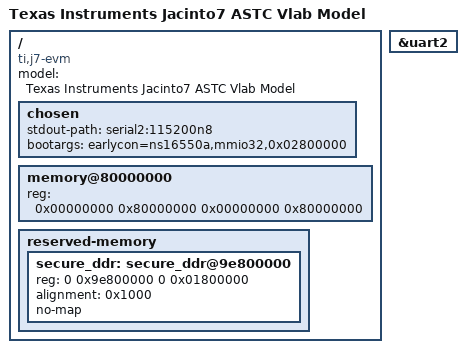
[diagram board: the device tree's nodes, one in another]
// SPDX-License-Identifier: GPL-2.0
/*
 * Device Tree Source for Jacinto7 ASTC VLAB Model
 *
 * Copyright (C) 2016-2017 Texas Instruments Incorporated - http://www.ti.com/
 */

/dts-v1/;

#include "k3-j7.dtsi"
#include "k3-j7-hexa-core.dtsi"

/ {
	compatible =  "ti,j7-evm", "ti,j7";
	model = "Texas Instruments Jacinto7 ASTC Vlab Model";

	chosen {
		stdout-path = "serial2:115200n8";
		bootargs = "earlycon=ns16550a,mmio32,0x02800000";
	};

	memory@80000000 {
		device_type = "memory";
		/* Claim 2GB RAM -> MUST be in sync with Python script*/
		reg = <0x00000000 0x80000000 0x00000000 0x80000000>;
	};

	reserved-memory {
		#address-cells = <2>;
		#size-cells = <2>;
		ranges;
		secure_ddr: secure_ddr@9e800000 {
			reg = <0 0x9e800000 0 0x01800000>; /* for OP-TEE */
			alignment = <0x1000>;
			no-map;
		};
	};
};

&uart2 {
	status = "okay";
};
